# TZ10xx register map
File version: 0.1g
Registers are 32-bit, read-write, reset 0x0 unless marked. A register's access mark holds for its fields unless they carry their own. Offsets are from the block's base; [hi:lo] are bit positions; {n}, {i} and the like mark numbered series.

## gpio0
Base 0x4004B000
Same registers: gpio1 0x4004C000, gpio2 0x4004D000, gpio3 0x4004E000
{0x0+4i} GPIODATA[{i}] (i=0..255)
  [7:0] DATA — At reading: The logical product of the address to be accessed and terminal status can be read. PADDR[9:2] & GPIN[7:0] At writing: The logical product of the address to be accessed and written data is set for the terminal. PADDR[9:2] & PWDATA[7:0]
0x400 GPIODIR — GPIO Data Direction Register
  [7:0] DIR — Sets the data direction of each GPIO pin. 0b1: GPIO output 0b0: GPIO input
0x404 GPIOIS — GPIO Interrupt Sense Register
  [7:0] IS — Sets the interrupt detection method of each GPIO pin. GPIOIEV specifies other settings. 0b1: Level detection interrupt 0b0: Edge detection interrupt
0x408 GPIOIBE — GPIO Interrupt Both Edges Register
  [7:0] IBE — Sets both-edge interrupt of each GPIO pin. GPIOIEV determines the edge to be used. 0b1: Both-edge interrupt 0b0: Single edge interrupt
0x40C GPIOIEV — GPIO Interrupt Event Register
  [7:0] IEV — Sets the edge interrupt method of each GPIO pin. 0b1: Rising edge interrupt or High-level interrupt 0b0: Falling edge interrupt or low-level interrupt
0x410 GPIOIE — GPIO Interrupt Enable Register
  [7:0] IE — Sets interrupt enable/mask for each GPIO pin. 0b1: Does not mask the interrupt (interrupt enable) 0b0: Masks the interrupt (interrupt disable)
0x414 GPIORIS ro — GPIO Raw Interrupt Status Register
  [7:0] RIS — Interrupt status before masking for each GPIO pin 0b1: Interrupt request available 0b0: No interrupt request
0x418 GPIOMIS ro — GPIO Masked Interrupt Status Register
  [7:0] MIS — Interrupt status after masking for each GPIO pin 0b1: Interrupt request available 0b0: No interrupt request
0x41C GPIOIC — GPIO Interrupt Clear Register
  [7:0] IC — Clears an interrupt for each GPIO pin. 0b1: Clears the interrupt. 0b0: Does nothing.
0x600 GPIOITCR — GPIO Integration Test Control Register
  [0] ITEN — Integration test enable 0b1: Test mode 0b0: Normal operation
0x604 GPIOITIP1 — GPIO Integration test input read/set Register 1
  [7:0] GPAFOUT — For ITEM=1(Integration test mode), enables the GPAFOUT input signal to be controlled. At reading: Reads the output status of Mux at the GPAFOUT last stage. At writing: Enables alternate data to be written for GPAFOUT input. For ITEM=0(Normal mod), the GPAFOUT input status can be read intact. No operation for writing.
0x608 GPIOITIP2 — GPIO Integration test input read/set Register 2
  [7:0] nGPAFEN — For ITEM=1(Integration test mode), enables the nGPAFEN input signal to be controlled. At reading: Reads the output status of Mux at the nGPAFEN last stage. At writing: Enables alternate data to be written for nGPAFEN input. For ITEM=0(Normal mod), the nGPAFEN input status can be read intact. No operation for writing.
0x60C GPIOITOP1 — GPIO Integration test output read/set Register 1
  [7:0] GPIOMIS — For ITEM=1(Integration test mode), enables the GPIOMIS output signal to be controlled. At reading: Returns 0. At writing: Writes data to be output to GPIOMIS. For ITEM=0(Normal mod), no operation for writing.
0x610 GPIOITOP2 ro — GPIO Integration test output read/set Register 2
  [0] GPIOINTR — For ITEM=1(Integration test mode), enables the status of the GPIOINTR output signal to be read. At reading: Reads the GPIOINTR status (GPIOINTR is a signal with GPIOMIS[7:0] being ORed).
0x614 GPIOITOP3 — GPIO Integration test output read/set Register 3
  [7:0] GPAFIN — For ITEM=1(Integration test mode), enables the GPIOAFIN output signal to be controlled. At reading: Reads the output status of Mux at the GPAFIN last stage. AT writing: Writes data to be output to GPAFIN. For ITEM=0(Normal mod), the GPAFIN output status can be read intact. No operation for writing.
0xFE0 GPIOPERIPHID0 ro reset 0x61 — GPIO Peripheral ID0 Register
  [7:0] Partnumber0 — Peripheral ID (this register stores a value from a hardware viewpoint.) Partnumber(Lower) 061=>61
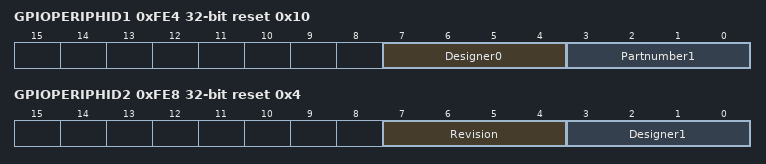
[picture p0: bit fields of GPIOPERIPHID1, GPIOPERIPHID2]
0xFE4 GPIOPERIPHID1 ro reset 0x10 — GPIO Peripheral ID1 Register
  [7:4] Designer0 — Peripheral ID (this register stores a value from a hardware viewpoint.) Designer(Lower) 41=>1
  [3:0] Partnumber1 — Peripheral ID (this register stores a value from a hardware viewpoint.) Partnumber(Upper) 061=>0
0xFE8 GPIOPERIPHID2 ro reset 0x4 — GPIO Peripheral ID2 Register
  [7:4] Revision — Peripheral ID (this register stores a value from a hardware viewpoint.) Revision: r1p0=>0
  [3:0] Designer1 — Peripheral ID (this register stores a value from a hardware viewpoint.) Designer(Upper) 41=>4
0xFEC GPIOPERIPHID3 ro — GPIO Peripheral ID3 Register
  [7:0] Configuration — Peripheral ID (this register stores a value from a hardware viewpoint.) Configuration: 00
0xFF0 GPIOPCELLID0 ro reset 0xD — GPIO PrimeCell ID0 Register
  [7:0] PCellID0 — PrimeCell ID (this register stores a value from a hardware viewpoint). Fixed value.
0xFF4 GPIOPCELLID1 ro reset 0xF0 — GPIO PrimeCell ID1 Register
  [7:0] PCellID1 — PrimeCell ID (this register stores a value from a hardware viewpoint). Fixed value.
0xFF8 GPIOPCELLID2 ro reset 0x5 — GPIO PrimeCell ID2 Register
  [7:0] PCellID2 — PrimeCell ID (this register stores a value from a hardware viewpoint). Fixed value.
0xFFC GPIOPCELLID3 ro reset 0xB1 — GPIO PrimeCell ID3 Register
  [7:0] PCellID3 — PrimeCell ID (this register stores a value from a hardware viewpoint). Fixed value.
